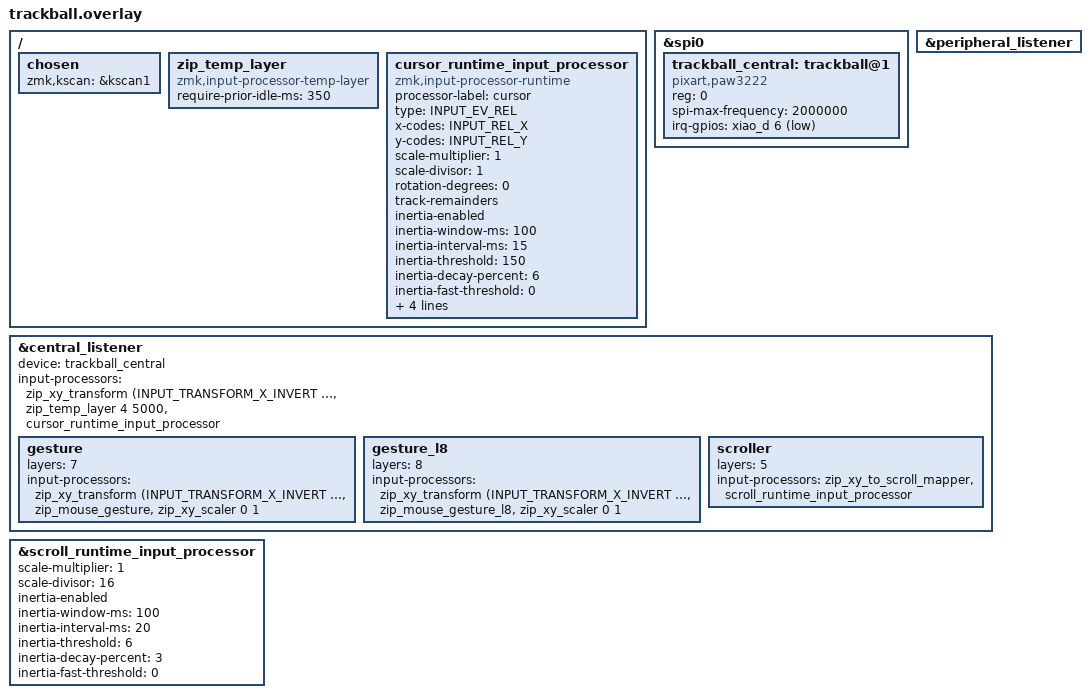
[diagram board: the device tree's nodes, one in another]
#include <input/processors/runtime-input-processor.dtsi>

/ {
    chosen {
        zmk,kscan = &kscan1;
    };
};

&spi0 {
    status = "okay";

    trackball_central: trackball@1 {
        status = "okay";
        compatible = "pixart,paw3222";
        reg = <0>;
        spi-max-frequency = <2000000>;
        irq-gpios = <&xiao_d 6 (GPIO_ACTIVE_LOW | GPIO_PULL_UP)>;
    };
};

// ペリフェラル（split経由）のリスナーを有効化
&peripheral_listener {
    status = "okay";
};

// セントラルのリスナーを有効化し、deviceを紐付け
// レイヤー番号は config/lism.keymap に対応（4=MOUSE, 5=SCROLL, 7/8=GESTURE）
&central_listener {
    status = "okay";
    device = <&trackball_central>;
    input-processors =
        <&zip_xy_transform (INPUT_TRANSFORM_X_INVERT | INPUT_TRANSFORM_Y_INVERT)>,
        <&zip_temp_layer 4 5000>,
        <&cursor_runtime_input_processor>;   // カーソル速度・慣性を DYA Studio（"cursor"）から調整

    gesture {
        layers = <7>;
        input-processors =
            <&zip_xy_transform (INPUT_TRANSFORM_X_INVERT | INPUT_TRANSFORM_Y_INVERT)>,
            <&zip_mouse_gesture>,
            <&zip_xy_scaler 0 1>;
    };

    gesture_l8 {
        layers = <8>;
        input-processors =
            <&zip_xy_transform (INPUT_TRANSFORM_X_INVERT | INPUT_TRANSFORM_Y_INVERT)>,
            <&zip_mouse_gesture_l8>,
            <&zip_xy_scaler 0 1>;
    };

    scroller {
        layers = <5>;
        input-processors =
            <&zip_xy_to_scroll_mapper>,
            <&scroll_runtime_input_processor>;   // スクロール速度などを DYA Studio から調整
    };
};

// トラックボールを動かすと MOUSE レイヤーを一時的に有効化（オートマウス）
/ {
    /omit-if-no-ref/ zip_temp_layer: zip_temp_layer {
        compatible = "zmk,input-processor-temp-layer";
        #input-processor-cells = <2>;
        require-prior-idle-ms = <350>;
    };
};
// ========================================
// DYA Studio から調整できるカーソル／スクロール処理の初期値
// ※カーソルは過去の "mouse" 保存設定を引き継がないよう、新ラベル "cursor" の processor を使う
// （DYA Studio の「トラックボール」で変更・保存した値がある場合はそちらが優先。
//   初期値に戻すには DYA Studio の「リセット」）
// ========================================


// スクロール: 速度 1/16（従来と同じ）＋慣性
&scroll_runtime_input_processor {
    scale-multiplier = <1>;
    scale-divisor = <16>;
    inertia-enabled;
    inertia-window-ms = <100>;
    inertia-interval-ms = <20>;
    inertia-threshold = <6>;           // スクロール量（1/16 後）で判定
    inertia-decay-percent = <3>;
    inertia-fast-threshold = <0>;
};

// カーソル: 素早く弾いたときだけ慣性で少し流れる
/ {
    cursor_runtime_input_processor: cursor_runtime_input_processor {
        compatible = "zmk,input-processor-runtime";
        processor-label = "cursor";
        type = <INPUT_EV_REL>;
        x-codes = <INPUT_REL_X>;
        y-codes = <INPUT_REL_Y>;
        scale-multiplier = <1>;
        scale-divisor = <1>;
        rotation-degrees = <0>;
        track-remainders;

        inertia-enabled;
        inertia-window-ms = <100>;       // 弾いた速さを測る時間
        inertia-interval-ms = <15>;      // 慣性で動かす間隔
        inertia-threshold = <150>;       // これ以上速く弾いたときだけ慣性が出る
        inertia-decay-percent = <6>;     // 1回ごとの減速率（小さいほど長く流れる）
        inertia-fast-threshold = <0>;    // 2段階目の加速は使わない

        temp-layer-transparent-behavior = <&trans>;
        temp-layer-kp-behavior = <&kp>;
        temp-layer-keep-keycodes = <LEFT_CONTROL LEFT_SHIFT LEFT_ALT LEFT_GUI RIGHT_CONTROL RIGHT_SHIFT RIGHT_ALT RIGHT_GUI>;

        #input-processor-cells = <0>;
    };
};
